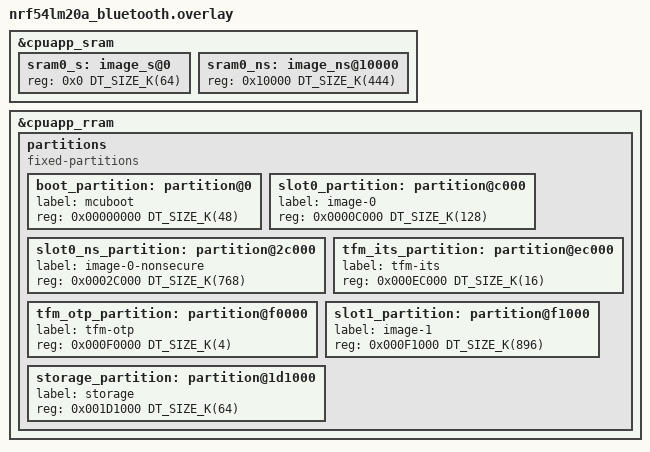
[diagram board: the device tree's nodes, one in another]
/*
 * Copyright (c) 2026 Nordic Semiconductor ASA
 *
 * SPDX-License-Identifier: LicenseRef-Nordic-5-Clause
 */

/*
 * Bluetooth-optimized TF-M partition layout for nRF54LM20A
 *
 * nRF54LM20A has 2036 kB of RRAM and 512 kB of SRAM (508 kB usable).
 * TrustZone flash region alignment: 4 kB (MPC-based)
 * TrustZone RAM region alignment:   4 kB
 * RRAM erase-block-size:            4 kB
 *
 * Optimized for Bluetooth LE applications with:
 * - Medium TF-M for BLE crypto (pairing, bonding)
 * - MCUboot for BLE DFU (SMP/FOTA)
 * - ITS for BLE bond storage
 * - No Protected Storage (bonds in ITS or NVS)
 * - Very large NS partition for BLE stack + application
 *
 * The large RRAM gives plenty of room for both the primary image
 * and a generous secondary DFU slot.
 *
 * Suitable for: BLE peripherals, audio devices, wearables
 */

&cpuapp_sram {
	sram0_s: image_s@0 {
		#address-cells = <1>;
		#size-cells = <1>;
		reg = <0x0 DT_SIZE_K(64)>;
		ranges = <0x0 0x0 DT_SIZE_K(64)>;
	};

	sram0_ns: image_ns@10000 {
		#address-cells = <1>;
		#size-cells = <1>;
		reg = <0x10000 DT_SIZE_K(444)>;
		ranges = <0x0 0x10000 DT_SIZE_K(444)>;
	};
};

&cpuapp_rram {
	partitions {
		compatible = "fixed-partitions";
		#address-cells = <1>;
		#size-cells = <1>;

		/*
		 * Flash layout (all addresses 4 kB aligned):
		 *
		 * 0x00000000  MCUboot bootloader        (48 kB)
		 * 0x0000C000  Primary slot:
		 *   0x0000C000  TF-M secure image       (128 kB)
		 *   0x0002C000  Non-secure BLE app       (768 kB)
		 * 0x000EC000  TF-M ITS                   (16 kB)
		 * 0x000F0000  TF-M OTP / NV counters      (4 kB)
		 * 0x000F1000  Secondary slot            (896 kB)
		 * 0x001D1000  Non-secure storage (NVS)    (64 kB)
		 *
		 * No TF-M PS — BLE bonds stored in ITS or NVS.
		 */

		boot_partition: partition@0 {
			label = "mcuboot";
			reg = <0x00000000 DT_SIZE_K(48)>;
		};

		slot0_partition: partition@c000 {
			label = "image-0";
			reg = <0x0000C000 DT_SIZE_K(128)>;
		};

		slot0_ns_partition: partition@2c000 {
			label = "image-0-nonsecure";
			reg = <0x0002C000 DT_SIZE_K(768)>;
		};

		tfm_its_partition: partition@ec000 {
			label = "tfm-its";
			reg = <0x000EC000 DT_SIZE_K(16)>;
		};

		tfm_otp_partition: partition@f0000 {
			label = "tfm-otp";
			reg = <0x000F0000 DT_SIZE_K(4)>;
		};

		slot1_partition: partition@f1000 {
			label = "image-1";
			reg = <0x000F1000 DT_SIZE_K(896)>;
		};

		storage_partition: partition@1d1000 {
			label = "storage";
			reg = <0x001D1000 DT_SIZE_K(64)>;
		};
	};
};
